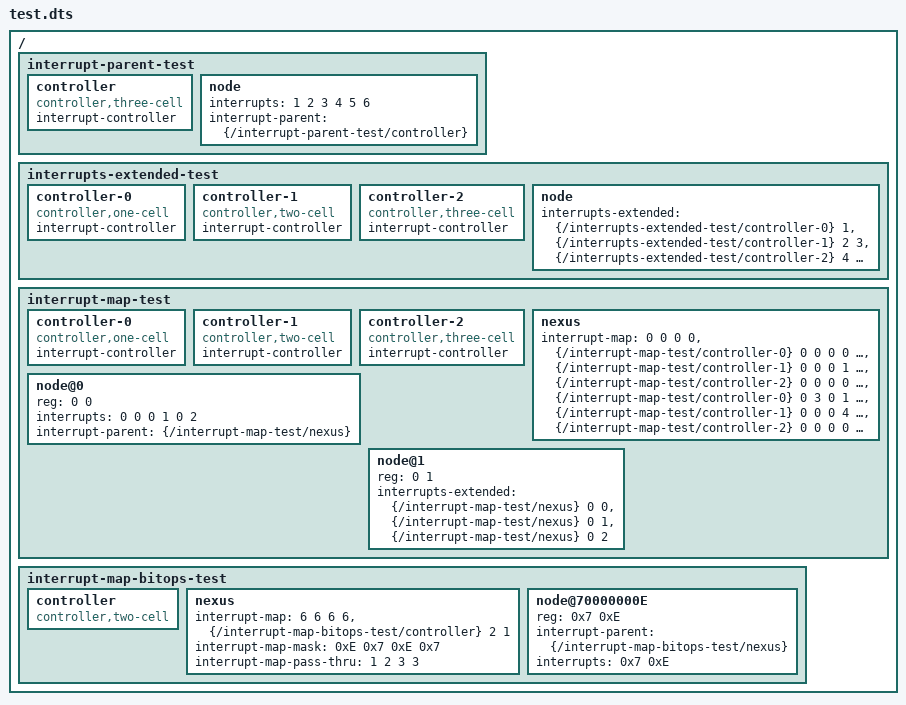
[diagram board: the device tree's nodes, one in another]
/dts-v1/;

/ {
	interrupt-parent-test {
		controller {
			compatible = "controller,three-cell";
			#interrupt-cells = <3>;
			interrupt-controller;
		};
		node {
			interrupts = <1 2 3 4 5 6>;
			interrupt-parent = <&{/interrupt-parent-test/controller}>;
		};
	};
	interrupts-extended-test {
		controller-0 {
			compatible = "controller,one-cell";
			#interrupt-cells = <1>;
			interrupt-controller;
		};
		controller-1 {
			compatible = "controller,two-cell";
			#interrupt-cells = <2>;
			interrupt-controller;
		};
		controller-2 {
			compatible = "controller,three-cell";
			#interrupt-cells = <3>;
			interrupt-controller;
		};
		node {
			interrupts-extended = <
				&{/interrupts-extended-test/controller-0} 1
				&{/interrupts-extended-test/controller-1} 2 3
				&{/interrupts-extended-test/controller-2} 4 5 6>;
		};
	};
	interrupt-map-test {
		#address-cells = <2>;
		#size-cells = <0>;

		controller-0 {
			compatible = "controller,one-cell";
			#address-cells = <1>;
			#interrupt-cells = <1>;
			interrupt-controller;
		};
		controller-1 {
			compatible = "controller,two-cell";
			#address-cells = <2>;
			#interrupt-cells = <2>;
			interrupt-controller;
		};
		controller-2 {
			compatible = "controller,three-cell";
			#address-cells = <3>;
			#interrupt-cells = <3>;
			interrupt-controller;
		};
		nexus {
			#interrupt-cells = <2>;
			interrupt-map = <
				0 0  0 0  &{/interrupt-map-test/controller-0}  0      0
				0 0  0 1  &{/interrupt-map-test/controller-1}  0 0    0 1
				0 0  0 2  &{/interrupt-map-test/controller-2}  0 0 0  0 0 2
				0 1  0 0  &{/interrupt-map-test/controller-0}  0      3
				0 1  0 1  &{/interrupt-map-test/controller-1}  0 0    0 4
				0 1  0 2  &{/interrupt-map-test/controller-2}  0 0 0  0 0 5>;
		};
		node@0 {
			reg = <0 0>;
			interrupts = <0 0 0 1 0 2>;
			interrupt-parent = <&{/interrupt-map-test/nexus}>;
		};
		node@1 {
			reg = <0 1>;
			interrupts-extended = <
			    &{/interrupt-map-test/nexus} 0 0
			    &{/interrupt-map-test/nexus} 0 1
			    &{/interrupt-map-test/nexus} 0 2>;
		};
	};
	interrupt-map-bitops-test {
		#address-cells = <2>;
		#size-cells = <0>;

		controller {
			compatible = "controller,two-cell";
			#address-cells = <0>;
			#interrupt-cells = <2>;
		};
		nexus {
			#interrupt-cells = <2>;
			interrupt-map = <
			    6 6  6 6  &{/interrupt-map-bitops-test/controller}  2 1
			>;
			interrupt-map-mask = <0xE 0x7 0xE 0x7>;
			// Not specified in the DT spec., but shows up due to common code
			// with GPIO. Might as well test it here.
			interrupt-map-pass-thru = <1 2 3 3>;
		};
		// Child unit specifier: 00000007 0000000E 00000007 0000000E
		// Mask:                 0000000E 00000007 0000000E 00000007
		// Pass-thru:            00000001 00000002 00000003 00000003
		node@70000000E {
			reg = <0x7 0xE>;
			interrupt-parent = <&{/interrupt-map-bitops-test/nexus}>;
			interrupts = <0x7 0xE>;
		};
	};
};

// TODO: Include full path in __repr__() for Devices?
